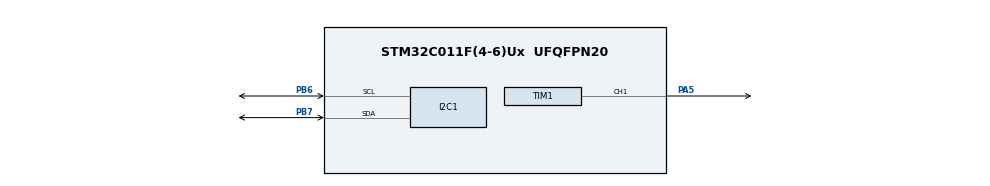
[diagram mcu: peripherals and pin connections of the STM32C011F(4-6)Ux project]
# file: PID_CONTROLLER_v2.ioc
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I2C1.Timing=0x00000000
Mcu.Family=STM32C0
Mcu.Name=STM32C011F(4-6)Ux
Mcu.Package=UFQFPN20
PA13.Mode=Serial_Wire
PA13.Signal=DEBUG_SWDIO
PA14-BOOT0.Mode=Serial_Wire
PA14-BOOT0.Signal=DEBUG_SWCLK
PA5.Signal=S_TIM1_CH1
PB6.Mode=I2C
PB6.Signal=I2C1_SCL
PB7.Mode=I2C
PB7.Signal=I2C1_SDA
ProjectManager.HeapSize=0x200
ProjectManager.StackSize=0x400
ProjectManager.TargetToolchain=STM32CubeIDE
RCC.ADCFreq_Value=32000
RCC.AHBFreq_Value=32000
RCC.CortexFreq_Value=32000
RCC.EXTERNAL_CLOCK_VALUE=12288000
RCC.HCLKFreq_Value=32000
RCC.HSE_VALUE=8000000
RCC.HSI_VALUE=48000000
RCC.LSE_VALUE=32768
RCC.SYSCLKFreq_VALUE=32000
RCC.SYSCLKSource=RCC_SYSCLKSOURCE_LSI
SH.S_TIM1_CH1.0=TIM1_CH1,PWM Generation1 CH1
TIM1.Channel-PWM\ Generation1\ CH1=TIM_CHANNEL_1
VP_TIM1_VS_ClockSourceINT.Mode=Internal
board=custom

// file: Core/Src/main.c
/* USER CODE BEGIN Header */
/**
  ******************************************************************************
  * @file           : main.c
  * @brief          : Main program body
  ******************************************************************************
  * @attention
  *
  * Copyright (c) 2023 STMicroelectronics.
  * All rights reserved.
  *
  * This software is licensed under terms that can be found in the LICENSE file
  * in the root directory of this software component.
  * If no LICENSE file comes with this software, it is provided AS-IS.
  *
  ******************************************************************************
  */
/* USER CODE END Header */
#include "main.h"

/* USER CODE BEGIN Includes */
#include "MC3630.h"
/* USER CODE END Includes */

I2C_HandleTypeDef hi2c1;

TIM_HandleTypeDef htim1;

void SystemClock_Config(void);
static void MX_GPIO_Init(void);
static void MX_I2C1_Init(void);
static void MX_TIM1_Init(void);

int main(void)
{

  /* MCU Configuration--------------------------------------------------------*/

  /* Reset of all peripherals, Initializes the Flash interface and the Systick. */
  HAL_Init();

  /* Configure the system clock */
  SystemClock_Config();

  /* Initialize all configured peripherals */
  MX_GPIO_Init();
  MX_I2C1_Init();
  MX_TIM1_Init();

  /* Infinite loop */
  while (1)
  {

  }
}

void SystemClock_Config(void)
{
  RCC_OscInitTypeDef RCC_OscInitStruct = {0};
  RCC_ClkInitTypeDef RCC_ClkInitStruct = {0};

  /** Initializes the RCC Oscillators according to the specified parameters
  * in the RCC_OscInitTypeDef structure.
  */
  RCC_OscInitStruct.OscillatorType = RCC_OSCILLATORTYPE_LSI;
  RCC_OscInitStruct.LSIState = RCC_LSI_ON;

  if (HAL_RCC_OscConfig(&RCC_OscInitStruct) != HAL_OK)
  {
    Error_Handler();
  }

  /** Initializes the CPU, AHB and APB buses clocks
  */
  RCC_ClkInitStruct.ClockType = RCC_CLOCKTYPE_HCLK|RCC_CLOCKTYPE_SYSCLK
                              |RCC_CLOCKTYPE_PCLK1;
  RCC_ClkInitStruct.SYSCLKSource = RCC_SYSCLKSOURCE_LSI;
  RCC_ClkInitStruct.SYSCLKDivider = RCC_SYSCLK_DIV1;
  RCC_ClkInitStruct.AHBCLKDivider = RCC_HCLK_DIV1;
  RCC_ClkInitStruct.APB1CLKDivider = RCC_APB1_DIV1;

  if (HAL_RCC_ClockConfig(&RCC_ClkInitStruct, FLASH_LATENCY_0) != HAL_OK)
  {
    Error_Handler();
  }
}

static void MX_I2C1_Init(void)
{

  hi2c1.Instance = I2C1;
  hi2c1.Init.Timing = 0x00000000;
  hi2c1.Init.OwnAddress1 = 0;
  hi2c1.Init.AddressingMode = I2C_ADDRESSINGMODE_7BIT;
  hi2c1.Init.DualAddressMode = I2C_DUALADDRESS_DISABLE;
  hi2c1.Init.OwnAddress2 = 0;
  hi2c1.Init.OwnAddress2Masks = I2C_OA2_NOMASK;
  hi2c1.Init.GeneralCallMode = I2C_GENERALCALL_DISABLE;
  hi2c1.Init.NoStretchMode = I2C_NOSTRETCH_DISABLE;
  if (HAL_I2C_Init(&hi2c1) != HAL_OK)
  {
    Error_Handler();
  }

  /** Configure Analogue filter
  */
  if (HAL_I2CEx_ConfigAnalogFilter(&hi2c1, I2C_ANALOGFILTER_ENABLE) != HAL_OK)
  {
    Error_Handler();
  }

  /** Configure Digital filter
  */
  if (HAL_I2CEx_ConfigDigitalFilter(&hi2c1, 0) != HAL_OK)
  {
    Error_Handler();
  }

}

static void MX_TIM1_Init(void)
{

  TIM_ClockConfigTypeDef sClockSourceConfig = {0};
  TIM_MasterConfigTypeDef sMasterConfig = {0};
  TIM_OC_InitTypeDef sConfigOC = {0};
  TIM_BreakDeadTimeConfigTypeDef sBreakDeadTimeConfig = {0};

  htim1.Instance = TIM1;
  htim1.Init.Prescaler = 0;
  htim1.Init.CounterMode = TIM_COUNTERMODE_UP;
  htim1.Init.Period = 65535;
  htim1.Init.ClockDivision = TIM_CLOCKDIVISION_DIV1;
  htim1.Init.RepetitionCounter = 0;
  htim1.Init.AutoReloadPreload = TIM_AUTORELOAD_PRELOAD_DISABLE;
  if (HAL_TIM_Base_Init(&htim1) != HAL_OK)
  {
    Error_Handler();
  }
  sClockSourceConfig.ClockSource = TIM_CLOCKSOURCE_INTERNAL;
  if (HAL_TIM_ConfigClockSource(&htim1, &sClockSourceConfig) != HAL_OK)
  {
    Error_Handler();
  }
  if (HAL_TIM_PWM_Init(&htim1) != HAL_OK)
  {
    Error_Handler();
  }
  sMasterConfig.MasterOutputTrigger = TIM_TRGO_RESET;
  sMasterConfig.MasterOutputTrigger2 = TIM_TRGO2_RESET;
  sMasterConfig.MasterSlaveMode = TIM_MASTERSLAVEMODE_DISABLE;
  if (HAL_TIMEx_MasterConfigSynchronization(&htim1, &sMasterConfig) != HAL_OK)
  {
    Error_Handler();
  }
  sConfigOC.OCMode = TIM_OCMODE_PWM1;
  sConfigOC.Pulse = 0;
  sConfigOC.OCPolarity = TIM_OCPOLARITY_HIGH;
  sConfigOC.OCNPolarity = TIM_OCNPOLARITY_HIGH;
  sConfigOC.OCFastMode = TIM_OCFAST_DISABLE;
  sConfigOC.OCIdleState = TIM_OCIDLESTATE_RESET;
  sConfigOC.OCNIdleState = TIM_OCNIDLESTATE_RESET;
  if (HAL_TIM_PWM_ConfigChannel(&htim1, &sConfigOC, TIM_CHANNEL_1) != HAL_OK)
  {
    Error_Handler();
  }
  sBreakDeadTimeConfig.OffStateRunMode = TIM_OSSR_DISABLE;
  sBreakDeadTimeConfig.OffStateIDLEMode = TIM_OSSI_DISABLE;
  sBreakDeadTimeConfig.LockLevel = TIM_LOCKLEVEL_OFF;
  sBreakDeadTimeConfig.DeadTime = 0;
  sBreakDeadTimeConfig.BreakState = TIM_BREAK_DISABLE;
  sBreakDeadTimeConfig.BreakPolarity = TIM_BREAKPOLARITY_HIGH;
  sBreakDeadTimeConfig.BreakFilter = 0;
  sBreakDeadTimeConfig.BreakAFMode = TIM_BREAK_AFMODE_INPUT;
  sBreakDeadTimeConfig.Break2State = TIM_BREAK2_DISABLE;
  sBreakDeadTimeConfig.Break2Polarity = TIM_BREAK2POLARITY_HIGH;
  sBreakDeadTimeConfig.Break2Filter = 0;
  sBreakDeadTimeConfig.Break2AFMode = TIM_BREAK_AFMODE_INPUT;
  sBreakDeadTimeConfig.AutomaticOutput = TIM_AUTOMATICOUTPUT_DISABLE;
  if (HAL_TIMEx_ConfigBreakDeadTime(&htim1, &sBreakDeadTimeConfig) != HAL_OK)
  {
    Error_Handler();
  }
  HAL_TIM_MspPostInit(&htim1);

}

static void MX_GPIO_Init(void)
{

  /* GPIO Ports Clock Enable */
  __HAL_RCC_GPIOA_CLK_ENABLE();
  __HAL_RCC_GPIOB_CLK_ENABLE();

}

void Error_Handler(void)
{
  __disable_irq();
  while (1)
  {
  }
}
